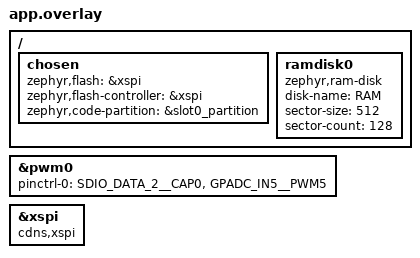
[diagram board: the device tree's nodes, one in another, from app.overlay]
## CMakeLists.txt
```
# Copyright (c) 2026 Synaptics Incorporated
# SPDX-License-Identifier: Apache-2.0

cmake_minimum_required(VERSION 3.20.0)

add_compile_definitions(
  PINCTRL_STATE_ACTIVE=PINCTRL_STATE_PRIV_START
  PINCTRL_STATE_ACTIVE_NAME=active
)

list(APPEND EXTRA_ZEPHYR_MODULES
	${CMAKE_CURRENT_SOURCE_DIR}/../../../modules/fs/fatfs
	$ENV{ZEPHYR_BASE}/../optional/modules/lib/tflite-micro
)

list(PREPEND DTC_OVERLAY_FILE ${CMAKE_CURRENT_SOURCE_DIR}/app.overlay)

find_package(Zephyr REQUIRED HINTS $ENV{ZEPHYR_BASE})
project(srw1500_smoke_test)

target_sources(app PRIVATE src/main.c src/cache/cache_benchmark.c)

if(CONFIG_TENSORFLOW_LITE_MICRO AND CONFIG_ETHOS_U)
	target_include_directories(app PRIVATE
		${CMAKE_CURRENT_SOURCE_DIR}/src/npu
		${CMAKE_CURRENT_SOURCE_DIR}/src/npu/models/keyword_spotting_cnn_small_int8
	)
	target_sources(app PRIVATE
		src/npu_test.cpp
		src/npu/inference_process.cpp
	)
endif()
target_include_directories(app PRIVATE
	${CMAKE_CURRENT_SOURCE_DIR}/../../../modules/fs/fatfs/include
)
```

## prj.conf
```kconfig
CONFIG_USERSPACE=y
CONFIG_ASSERT=y
CONFIG_COMMON_LIBC_MALLOC_ARENA_SIZE=65536

# Shell configuration
CONFIG_SHELL=y
CONFIG_SHELL_BACKEND_SERIAL=y
CONFIG_SHELL_STACK_SIZE=8192
CONFIG_BOOT_BANNER=y
CONFIG_SHELL_PROMPT_UART="Srw1500:$ "
CONFIG_SHELL_HISTORY=y
CONFIG_SHELL_HISTORY_BUFFER=512
CONFIG_LOG=y
# Synchronous output so early-boot and fault-path messages are not lost.
CONFIG_LOG_MODE_IMMEDIATE=y
CONFIG_LOG_MODE_MINIMAL=n

# Syscounter
# Slowclock timer
# Timer
CONFIG_COUNTER=y

# GPIO
CONFIG_GPIO=y

# I2C
CONFIG_I2C=y
CONFIG_I2C_TARGET=y

# SPI
CONFIG_SPI=y

# Watchdog
CONFIG_WATCHDOG=y
CONFIG_WDOG_CMSDK_SYNA=y

# PWM
CONFIG_PWM=y
CONFIG_PWM_CAPTURE=y

# Mailbox to secure co-processor (SPROT_MBOX)
CONFIG_MBOX=y

# OTP Provisioning
CONFIG_OTP_PROVISIONED_ENABLED=n
CONFIG_OTP_PROVISIONED_V2_ENABLED=y
CONFIG_OTP_PROVISIONED_DISABLED=n
CONFIG_OTP=y
CONFIG_OTP_SHELL=y
CONFIG_OTP_PROGRAM=y

# File System
CONFIG_FILE_SYSTEM=y
CONFIG_FILE_SYSTEM_SHELL=y

# RAM FS
CONFIG_FILE_SYSTEM_MKFS=y

# Pinctrl
CONFIG_PINCTRL=y
CONFIG_PINCTRL_DYNAMIC=y

# Flash
CONFIG_FLASH=y
CONFIG_FLASH_MAP=y
CONFIG_FLASH_MAP_CUSTOM=y
CONFIG_FLASH_PAGE_LAYOUT=y

# LittleFS
CONFIG_FILE_SYSTEM_LITTLEFS=y

# LittleFS tuning
CONFIG_FS_LITTLEFS_READ_SIZE=256
CONFIG_FS_LITTLEFS_PROG_SIZE=256
CONFIG_FS_LITTLEFS_CACHE_SIZE=256
CONFIG_FS_LITTLEFS_LOOKAHEAD_SIZE=32
CONFIG_FS_LITTLEFS_BLOCK_CYCLES=512

# Disable RWW feature here if required. By default it is enabled.
# CONFIG_CDNS_XSPI_RWW=n
```

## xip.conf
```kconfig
CONFIG_FLASH_BASE_ADDRESS=0x38000000
CONFIG_FLASH_SIZE=32768
CONFIG_USE_DT_CODE_PARTITION=y
```

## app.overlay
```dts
/*
 * Copyright (c) 2026 Synaptics Incorporated
 *
 * SPDX-License-Identifier: Apache-2.0
 */

/ {
	chosen {
		zephyr,flash = &xspi;
		zephyr,flash-controller = &xspi;
		zephyr,code-partition = &slot0_partition;
	};

	ramdisk0 {
		compatible = "zephyr,ram-disk";
		disk-name = "RAM";
		sector-size = <512>;
		sector-count = <128>;
	};
};

/* GPIO18 shares SDIO_DATA_2; reserve it as CAP0 only for this smoke test. */
&pwm0 {
	pinctrl-0 = <&SDIO_DATA_2__CAP0 &GPADC_IN5__PWM5>;
	pinctrl-names = "default";
};

&xspi {
	compatible = "cdns,xspi", "soc-nv-flash";
	status = "okay";
};
```

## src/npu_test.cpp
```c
/*
 * Copyright (c) 2026 Synaptics Incorporated
 *
 * SPDX-License-Identifier: Apache-2.0
 */

#include "npu_test.h"

#include "inference_process.hpp"

#include <errno.h>
#include <stdio.h>
#include <string>
#include <vector>

#include <zephyr/kernel.h>

#include "input.h"
#include "model.h"
#include "output.h"

using namespace InferenceProcess;

#define NUM_INFERENCE_TASKS 1

#define TENSOR_ARENA_SIZE_PER_INFERENCE TENSOR_ARENA_SIZE

namespace
{
constexpr size_t arenaSize = TENSOR_ARENA_SIZE_PER_INFERENCE;

TENSOR_ARENA_ATTR uint8_t tensorArena[arenaSize];
}

extern "C" int npu_tflm_ethosu_test(void)
{
	InferenceJob job(modelName,
			 DataPtr(const_cast<uint8_t *>(networkModelData), sizeof(networkModelData)),
			 { DataPtr(const_cast<uint8_t *>(inputData), sizeof(inputData)) }, {},
			 { DataPtr(const_cast<uint8_t *>(expectedOutputData),
				   sizeof(expectedOutputData)) });
	InferenceProcess::InferenceProcess inferenceProcess(tensorArena, arenaSize);

	printf("Running TFLM Ethos-U model: %s\n", modelName);

	if (inferenceProcess.runJob(job)) {
		printf("TFLM Ethos-U inference failed\n");
		return -EIO;
	}

	printf("TFLM Ethos-U inference passed\n");
	return 0;
}
```

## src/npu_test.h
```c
/*
 * Copyright (c) 2026 Synaptics Incorporated
 *
 * SPDX-License-Identifier: Apache-2.0
 */

#ifndef SRW1500_SMOKE_TEST_NPU_TEST_H_
#define SRW1500_SMOKE_TEST_NPU_TEST_H_

#ifdef __cplusplus
extern "C" {
#endif

int npu_tflm_ethosu_test(void);

#ifdef __cplusplus
}
#endif

#endif /* SRW1500_SMOKE_TEST_NPU_TEST_H_ */
```
